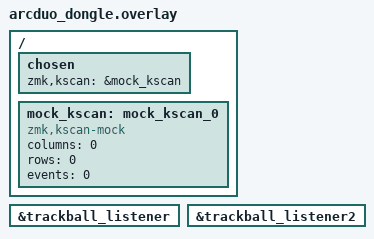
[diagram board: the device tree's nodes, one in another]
// vim: set ft=dts:

#include "arcduo.dtsi"

/ {
  chosen {
    zmk,kscan = &mock_kscan;
   };

  mock_kscan: mock_kscan_0 {
    compatible = "zmk,kscan-mock";
    columns = <0>;
    rows = <0>;
    events = <0>;
  };
};

&trackball_listener {
  status = "okay";
};

&trackball_listener2 {
  status = "okay";
};
